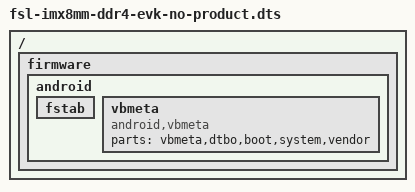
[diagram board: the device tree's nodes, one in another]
// SPDX-License-Identifier: GPL-2.0+
/*
 * Copyright 2019 NXP
 */

/dts-v1/;

#include "fsl-imx8mm-ddr4-evk.dts"

/ {
	firmware {
		android {
			fstab {
				/delete-node/ product;
			};
			vbmeta {
				/*we need use FirstStageMountVBootV2 if we enable avb*/
				compatible = "android,vbmeta";
				/*parts means the partition witch can be mount in first stage*/
				parts = "vbmeta,dtbo,boot,system,vendor";
			};
		};
	};
};
